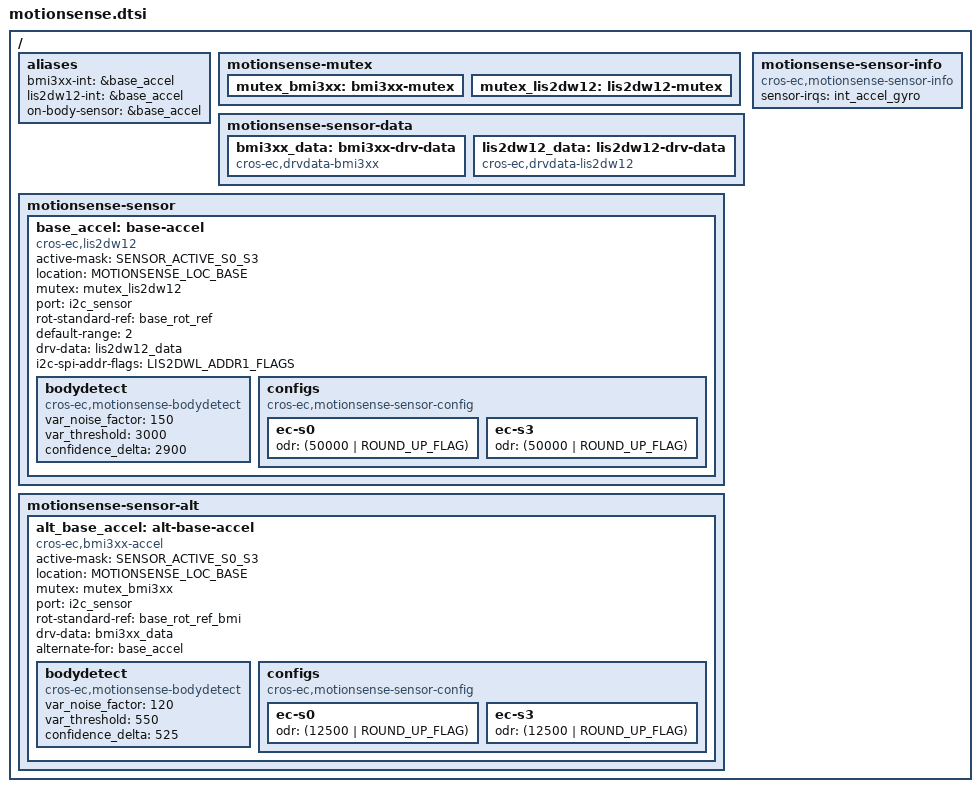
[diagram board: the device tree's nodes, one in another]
/* Copyright 2022 The ChromiumOS Authors
 * Use of this source code is governed by a BSD-style license that can be
 * found in the LICENSE file.
 */

#include <dt-bindings/motionsense/utils.h>


/ {
	aliases {
		/*
		 * motion sense's <>_INT_EVENT is handled
		 * by alias. Using the alias, each driver creates
		 * its own <>_INT_EVENT.
		 */
		bmi3xx-int = &base_accel;
		lis2dw12-int = &base_accel;

		/* Use base accelerometer for on-body sensor */
		on-body-sensor = &base_accel;
	};

	/*
	 * Declare mutexes used by sensor drivers.
	 * A mutex node is used to create an instance of mutex_t.
	 * A mutex node is referenced by a sensor node if the
	 * corresponding sensor driver needs to use the
	 * instance of the mutex.
	 */
	motionsense-mutex {
		mutex_bmi3xx: bmi3xx-mutex {
		};
		mutex_lis2dw12: lis2dw12-mutex {
		};
	};

	/*
	 * Driver specific data. A driver-specific data can be shared with
	 * different motion sensors while they are using the same driver.
	 *
	 * If a node's compatible starts with "cros-ec,accelgyro-", it is for
	 * a common structure defined in accelgyro.h.
	 * e.g) compatible = "cros-ec,accelgyro-als-drv-data" is for
	 * "struct als_drv_data_t" in accelgyro.h
	 */
	motionsense-sensor-data {
		bmi3xx_data: bmi3xx-drv-data {
			compatible = "cros-ec,drvdata-bmi3xx";
			status = "okay";
		};
		lis2dw12_data: lis2dw12-drv-data {
			compatible = "cros-ec,drvdata-lis2dw12";
			status = "okay";
		};
	};

	/*
	 * List of motion sensors that creates motion_sensors array.
	 * The nodelabel "lid_accel" and "base_accel" are used to indicate
	 * motion sensor IDs for lid angle calculation.
	 */
	motionsense-sensor {
		base_accel: base-accel {
			compatible = "cros-ec,lis2dw12";
			status = "okay";

			active-mask = "SENSOR_ACTIVE_S0_S3";
			location = "MOTIONSENSE_LOC_BASE";
			mutex = <&mutex_lis2dw12>;
			port = <&i2c_sensor>;
			rot-standard-ref = <&base_rot_ref>;
			default-range = <2>;
			drv-data = <&lis2dw12_data>;
			i2c-spi-addr-flags = "LIS2DWL_ADDR1_FLAGS";
			bodydetect {
				compatible = "cros-ec,motionsense-bodydetect";
				status = "okay";
				var_noise_factor = <150>;
				var_threshold = <3000>;
				confidence_delta = <2900>;
			};
			configs {
				compatible =
					"cros-ec,motionsense-sensor-config";
				/* 50 Hz to support body detection. */
				ec-s0 {
					odr = <(50000 | ROUND_UP_FLAG)>;
				};
				ec-s3 {
					odr = <(50000 | ROUND_UP_FLAG)>;
				};
			};
		};
	};

	motionsense-sensor-alt {
		alt_base_accel: alt-base-accel {
			compatible = "cros-ec,bmi3xx-accel";
			status = "okay";

			active-mask = "SENSOR_ACTIVE_S0_S3";
			location = "MOTIONSENSE_LOC_BASE";
			mutex = <&mutex_bmi3xx>;
			port = <&i2c_sensor>;
			rot-standard-ref = <&base_rot_ref_bmi>;
			drv-data = <&bmi3xx_data>;
			alternate-for = <&base_accel>;
			bodydetect {
				compatible = "cros-ec,motionsense-bodydetect";
				status = "okay";
				var_noise_factor = <120>;
				var_threshold = <550>;
				confidence_delta = <525>;
			};
			configs {
				compatible =
					"cros-ec,motionsense-sensor-config";
				ec-s0 {
					odr = <(12500 | ROUND_UP_FLAG)>;
				};
				ec-s3 {
					odr = <(12500 | ROUND_UP_FLAG)>;
				};
			};
		};
	};

	motionsense-sensor-info {
		compatible = "cros-ec,motionsense-sensor-info";

		/*
		 * list of GPIO interrupts that have to
		 * be enabled at initial stage
		 */
		sensor-irqs = <&int_accel_gyro>;
	};
};
